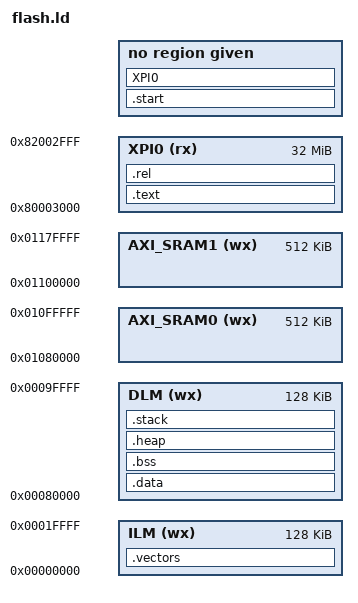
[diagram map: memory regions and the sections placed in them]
/*
 * Copyright 2021 hpmicro
 * SPDX-License-Identifier: BSD-3-Clause
 */

ENTRY(_start)

STACK_SIZE = DEFINED(_stack_size) ? _stack_size : 0x4000;
HEAP_SIZE = DEFINED(_heap_size) ? _heap_size : 0x4000;
RAM_VECTOR_SIZE = DEFINED(_ram_vector_size) ? _ram_vector_size : 0x4000;

MEMORY
{
    XPI0 (rx) : ORIGIN = 0x80003000, LENGTH = 32M 
    ILM (wx) : ORIGIN = 0, LENGTH = 128K
    DLM (wx) : ORIGIN = 0x80000, LENGTH = 128K
    AXI_SRAM0 (wx) : ORIGIN = 0x1080000, LENGTH = 512K
    AXI_SRAM1 (wx) : ORIGIN = 0x1100000, LENGTH = 512K
}

SECTIONS
{
    .start : {
        . = ALIGN(8);
        KEEP(*(.start))
    } XPI0

    .vectors ORIGIN(ILM) : AT(ORIGIN(XPI0)) {
        . = ALIGN(8);
        __vector_load_start__ = .;
        KEEP(*(.isr_vector))
        KEEP(*(.vector_table))
        . = ALIGN(8);
        __vector_load_end__ = .;
    } > ILM

    .text ORIGIN(XPI0) + (__vector_load_end__ - __vector_load_start__) : {
        . = ALIGN(8);
        *(.text)
        *(.text*)
        *(.rodata)
        *(.rodata*)
        *(.srodata)
        *(.srodata*)

        *(.hash)
        *(.dyn*)
        *(.gnu*)
        *(.pl*)

        KEEP(*(.eh_frame))
        *(.eh_frame*)

        KEEP (*(.init))
        KEEP (*(.fini))
        . = ALIGN(8);
    } > XPI0 

    .rel : {
        KEEP(*(.rel*))
    } > XPI0

    PROVIDE (__etext = .);
    PROVIDE (_etext = .);
    PROVIDE (etext = .);

    .data : AT(etext) {
        . = ALIGN(8);
        __data_start__ = .;
        *(.data)
        *(.data*)
        *(.sdata)
        *(.sdata*)
        *(.tdata)
        *(.tdata*)

        KEEP(*(.jcr))
        KEEP(*(.dynamic))
        KEEP(*(.got*))
        KEEP(*(.got))
        KEEP(*(.gcc_execpt_table))
        KEEP(*(.gcc_execpt_table.*))

        PROVIDE(__preinit_array_start = .);
        KEEP(*(.preinit_array))
        PROVIDE(__preinit_array_end = .);

        PROVIDE(__init_array_start = .);
        KEEP(*(SORT_BY_INIT_PRIORITY(.init_array.*)))
        KEEP(*(.init_array))
        PROVIDE(__init_array_end = .);

        PROVIDE(__finit_array_start = .);
        KEEP(*(SORT_BY_INIT_PRIORITY(.finit_array.*)))
        KEEP(*(.finit_array))
        PROVIDE(__finit_array_end = .);

        KEEP(*crtbegin*.o(.ctors))
        KEEP(*(EXCLUDE_FILE (*crtend*.o) .ctors))
        KEEP(*(SORT(.ctors.*)))
        KEEP(*(.ctors))

        KEEP(*crtbegin*.o(.dtors))
        KEEP(*(EXCLUDE_FILE (*crtend*.o) .dtors))
        KEEP(*(SORT(.dtors.*)))
        KEEP(*(.dtors))

        . = ALIGN(8);
        __data_end__ = .;
        PROVIDE (__edata = .);
        PROVIDE (_edata = .);
        PROVIDE (edata = .);
    } > DLM

    .bss : {
        . = ALIGN(8);
        __bss_start__ = .;
        *(.bss)
        *(.bss*)
        *(.tbss*)
        *(.sbss*)
        *(.scommon)
        *(.scommon*)
        *(.tcommon*)
        *(.dynsbss*)
        *(COMMON)
        . = ALIGN(8);
        _end = .;
        __bss_end__ = .;
    } > DLM

    .heap : {
        . = ALIGN(8);
        __heap_start__ = .;
        . += HEAP_SIZE;
        __heap_end__ = .;

    } > DLM

    .stack : {
        . = ALIGN(8);
        __stack_base__ = .;
        . += STACK_SIZE;
        PROVIDE (_stack = .);
        PROVIDE (_stack_in_dlm = .);
    } > DLM

    ASSERT(__stack_base__ >= __heap_end__, "stack overlapped with heap")
}
